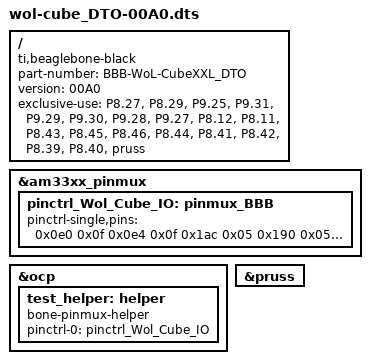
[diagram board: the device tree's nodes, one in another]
/*
 * Copyright (C) 2012 Texas Instruments Incorporated - http://www.ti.com/
 *
 * This program is free software; you can redistribute it and/or modify
 * it under the terms of the GNU General Public License version 2 as
 * published by the Free Software Foundation.
 */

/dts-v1/;
/plugin/;

/{
          
          compatible = "ti,beaglebone-black";
          part-number = "BBB-WoL-CubeXXL_DTO";
          version = "00A0";
          //board-name = "BBB-Wol-CubeXXL-Carrier";
          //manufacturer = "RT-Labor";
     
       exclusive-use =
                /* the pin header uses */
                "P8.27", /* Reset0 GPIO_OUT */
                "P8.29", /* Reset1 GPIO_OUT */
                "P9.25", /* Latch0 Pru0 */
                "P9.31", /* SCKL0  PRU0 */
                "P9.29", /* SDO0_0 PRU0 */
		"P9.30", /* SDO0_1 PRU0 */
                "P9.28", /* SDO0_2 PRU0 */
                "P9.27", /* SDO0_3 PRU0 */
                "P8.12", /* SDO0_4 PRU0 */
                "P8.11", /* SDO0_5 PRU0 */
                "P8.43", /* LATCH1 PRU1 */
                "P8.45", /* SCKL1  PRU1 */
                "P8.46", /* SDO1_0 PRU1 */
                "P8.44", /* SDO1_1 PRU1 */
                "P8.41", /* SDO1_2 PRU1 */
                "P8.42", /* SDO1_3 PRU1 */
                "P8.39", /* SDO1_4 PRU1 */
                "P8.40", /* SDO1_5 PRU1 */
                "pruss";

       fragment@0 {
             target = <&am33xx_pinmux>;            
             __overlay__ {
                  pinctrl_Wol_Cube_IO: pinmux_BBB {
			pinctrl-single,pins = <
                                /*adr mode   register   gpio     header Pin function*/ 
                                0x0e0 0x0f /*PRU1-r30-8	GPIO2_22  P8-27 U5  Reset0 GPIO_OUT*/
                                0x0e4 0x0f /*PRU1-r30-9	GPIO2_23  P8-29 R5  Reset1 GPIO_OUT*/
                                0x1ac 0x05 /*PRU0-r30-7 GPIO3_21  P9-25 A14 LATCH0 PRU0 */
                                0x190 0x05 /*PRU1-r30-0	GPIO3_14  P9-31 A13 SCKL0  PRU0 */
                                0x194 0x05 /*PRU0-r30-1	GPIO3_15  P9-29 B13 SDO0_0 PRU0 */
                                0x198 0x05 /*PRU0-r30-2	GPIO3_13  P9-30 D12 SDO0_1 PRU0 */
                                0x19c 0x05 /*PRU0-r30-3	GPIO3_17  P9-28 C12 SDO0_2 PRU0 */
                                0x1a4 0x05 /*PRU0-r30-5	GPIO3_19  P9-27 C13 SDO0_3 PRU0 */
                                0x030 0x06 /*PRU0-r30-14 GPIO1_12 P8-12 T12 SDO0_4 PRU0 */
                                0x034 0x06 /*PRU0-r30-15 GPIO1_13 P8-11	R12 SDO0_5 PRU0 */
                                0x0a8 0x05 /*PRU1-r30-2	GPIO2_8	  P8-43 R3  LATCH1 PRU1 */
                                0x0a0 0x05 /*PRU0-r30-0	GPIO2_6	  P8-45 R1  SCKL1  PRU1 */
                                0x0a4 0x05 /*PRU1-r30-1	GPIO2_7	  P8-46 R2  SDO1_0 PRU1 */
                                0x0ac 0x05 /*PRU1-r30-3	GPIO2_9	  P8-44 R4  SDO1_1 PRU1 */
                                0x0b0 0x05 /*PRU1-r30-4	GPIO2_10  P8-41 T1  SDO1_2 PRU1 */
                                0x0b4 0x05 /*PRU1-r30-5	GPIO2_11  P8-42 T2  SDO1_3 PRU1 */
                                0x0b8 0x05 /*PRU1-r30-6	GPIO2_12  P8-39 T3  SDO1_4 PRU1 */
                                0x0bc 0x05 /*PRU1-r30-7	GPIO2_13  P8-40 T4  SDO1_5 PRU1 */
                               /* OUTPUT  GPIO(mode7) 0x07 pulldown, 0x17 pullup, 0x?f no pullup/down */
			       /* INPUT   GPIO(mode7) 0x27 pulldown, 0x37 pullup, 0x?f no pullup/down */

			>;
		  };
             };
       };

       fragment@1 {
		target = <&ocp>;
		__overlay__ {
			test_helper: helper {
				compatible = "bone-pinmux-helper";
				pinctrl-names = "default";
				pinctrl-0 = <&pinctrl_Wol_Cube_IO>;
				status = "okay";
			};
		};
	};

        fragment@2 {
                 target = <&pruss>;
                 __overlay__ {
                         status = "okay";
                 };
        };
	
};
